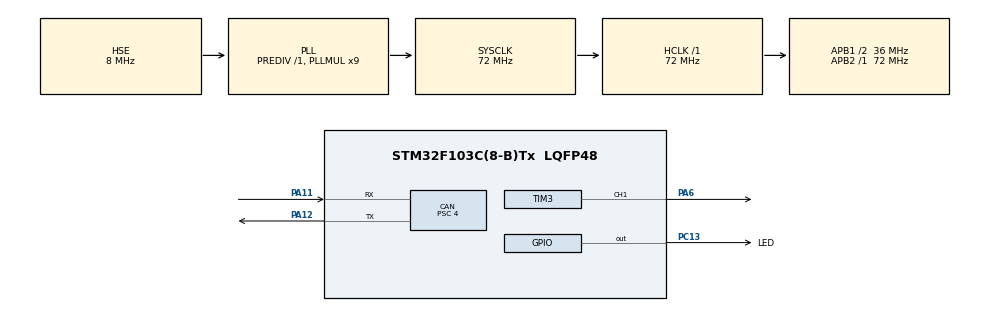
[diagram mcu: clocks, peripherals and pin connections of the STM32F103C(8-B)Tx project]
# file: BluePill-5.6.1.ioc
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CAN.ABOM=ENABLE
CAN.AWUM=ENABLE
CAN.BS1=CAN_BS1_6TQ
CAN.BS2=CAN_BS2_2TQ
CAN.CalculateTimeBit=1000
CAN.CalculateTimeQuantum=111.11111111111111
CAN.Prescaler=4
CAN.RFLM=ENABLE
Mcu.Family=STM32F1
Mcu.Name=STM32F103C(8-B)Tx
Mcu.Package=LQFP48
NVIC.CAN1_RX1_IRQn=true\:0\:0\:false\:false\:true\:true\:true
NVIC.PriorityGroup=NVIC_PRIORITYGROUP_4
NVIC.TIM2_IRQn=true\:0\:0\:false\:false\:true\:false\:true
NVIC.TimeBase=TIM2_IRQn
NVIC.TimeBaseIP=TIM2
NVIC.USB_LP_CAN1_RX0_IRQn=true\:0\:0\:false\:false\:true\:true\:true
PA11.Mode=Master
PA11.Signal=CAN_RX
PA12.Mode=Master
PA12.Signal=CAN_TX
PA13.Mode=JTAG_4_pins
PA13.Signal=SYS_JTMS-SWDIO
PA14.Mode=JTAG_4_pins
PA14.Signal=SYS_JTCK-SWCLK
PA15.Mode=JTAG_4_pins
PA15.Signal=SYS_JTDI
PA6.Signal=S_TIM3_CH1
PB3.Mode=JTAG_4_pins
PB3.Signal=SYS_JTDO-TRACESWO
PC13-TAMPER-RTC.GPIO_Label=LED
PC13-TAMPER-RTC.Signal=GPIO_Output
PD0-OSC_IN.Mode=HSE-External-Oscillator
PD0-OSC_IN.Signal=RCC_OSC_IN
PD1-OSC_OUT.Mode=HSE-External-Oscillator
PD1-OSC_OUT.Signal=RCC_OSC_OUT
ProjectManager.HeapSize=0x200
ProjectManager.StackSize=0x400
ProjectManager.TargetToolchain=Makefile
RCC.AHBFreq_Value=72000000
RCC.APB1CLKDivider=RCC_HCLK_DIV2
RCC.APB1Freq_Value=36000000
RCC.APB1TimFreq_Value=72000000
RCC.APB2Freq_Value=72000000
RCC.APB2TimFreq_Value=72000000
RCC.HCLKFreq_Value=72000000
RCC.PLLMUL=RCC_PLL_MUL9
RCC.PLLSourceVirtual=RCC_PLLSOURCE_HSE
RCC.SYSCLKFreq_VALUE=72000000
RCC.SYSCLKSource=RCC_SYSCLKSOURCE_PLLCLK
RCC.USBFreq_Value=72000000
SH.S_TIM3_CH1.0=TIM3_CH1,PWM Generation1 CH1
TIM3.Channel-PWM\ Generation1\ CH1=TIM_CHANNEL_1
TIM3.Period=3600
TIM3.Prescaler=399
VP_SYS_VS_tim2.Mode=TIM2
board=custom

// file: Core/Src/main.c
/* USER CODE BEGIN Header */
/**
  ******************************************************************************
  * @file           : main.c
  * @brief          : Main program body
  ******************************************************************************
  * @attention
  *
  * <h2><center>&copy; Copyright (c) 2020 STMicroelectronics.
  * All rights reserved.</center></h2>
  *
  * This software component is licensed by ST under BSD 3-Clause license,
  * the "License"; You may not use this file except in compliance with the
  * License. You may obtain a copy of the License at:
  *                        opensource.org/licenses/BSD-3-Clause
  *
  ******************************************************************************
  */
/* USER CODE END Header */

#include "main.h"
#include "can.h"
#include "tim.h"
#include "gpio.h"

/* USER CODE BEGIN Includes */
#include "os.h"
/* USER CODE END Includes */

void SystemClock_Config(void);

int main(void)
{

  /* MCU Configuration--------------------------------------------------------*/

  /* Reset of all peripherals, Initializes the Flash interface and the Systick. */
  HAL_Init();

  /* Configure the system clock */
  SystemClock_Config();

  /* USER CODE BEGIN SysInit */
  SEGGER_SYSVIEW_Conf();
  /* USER CODE END SysInit */

  /* Initialize all configured peripherals */
  MX_GPIO_Init();
  MX_TIM3_Init();
  MX_CAN_Init();
  /* USER CODE BEGIN 2 */

  startRTOS();
  /* USER CODE END 2 */

  /* Infinite loop */
  while (1)
  {

  }
}

void SystemClock_Config(void)
{
  RCC_OscInitTypeDef RCC_OscInitStruct = {0};
  RCC_ClkInitTypeDef RCC_ClkInitStruct = {0};

  /** Initializes the CPU, AHB and APB busses clocks
  */
  RCC_OscInitStruct.OscillatorType = RCC_OSCILLATORTYPE_HSE;
  RCC_OscInitStruct.HSEState = RCC_HSE_ON;
  RCC_OscInitStruct.HSEPredivValue = RCC_HSE_PREDIV_DIV1;
  RCC_OscInitStruct.HSIState = RCC_HSI_ON;
  RCC_OscInitStruct.PLL.PLLState = RCC_PLL_ON;
  RCC_OscInitStruct.PLL.PLLSource = RCC_PLLSOURCE_HSE;
  RCC_OscInitStruct.PLL.PLLMUL = RCC_PLL_MUL9;
  if (HAL_RCC_OscConfig(&RCC_OscInitStruct) != HAL_OK)
  {
    Error_Handler();
  }
  /** Initializes the CPU, AHB and APB busses clocks
  */
  RCC_ClkInitStruct.ClockType = RCC_CLOCKTYPE_HCLK|RCC_CLOCKTYPE_SYSCLK
                              |RCC_CLOCKTYPE_PCLK1|RCC_CLOCKTYPE_PCLK2;
  RCC_ClkInitStruct.SYSCLKSource = RCC_SYSCLKSOURCE_PLLCLK;
  RCC_ClkInitStruct.AHBCLKDivider = RCC_SYSCLK_DIV1;
  RCC_ClkInitStruct.APB1CLKDivider = RCC_HCLK_DIV2;
  RCC_ClkInitStruct.APB2CLKDivider = RCC_HCLK_DIV1;

  if (HAL_RCC_ClockConfig(&RCC_ClkInitStruct, FLASH_LATENCY_2) != HAL_OK)
  {
    Error_Handler();
  }
}

 /**
  * @brief  Period elapsed callback in non blocking mode
  * @note   This function is called  when TIM2 interrupt took place, inside
  * HAL_TIM_IRQHandler(). It makes a direct call to HAL_IncTick() to increment
  * a global variable "uwTick" used as application time base.
  * @param  htim : TIM handle
  * @retval None
  */
void HAL_TIM_PeriodElapsedCallback(TIM_HandleTypeDef *htim)
{
  if (htim->Instance == TIM2) {
    HAL_IncTick();
  }
}

void Error_Handler(void)
{
}

/************************ (C) COPYRIGHT STMicroelectronics *****END OF FILE****/
